# M2354 register map
File version: 1.0
Registers are 32-bit, read-write, reset 0x0 unless marked. A register's access mark holds for its fields unless they carry their own. Offsets are from the block's base; [hi:lo] are bit positions; lines under a group give offsets from that group; {n}, {i} and the like mark numbered series; 'fields as' and 'values as' point back to an identical list.

## CLK_NS — CLK Register Map
Base 0x50000200
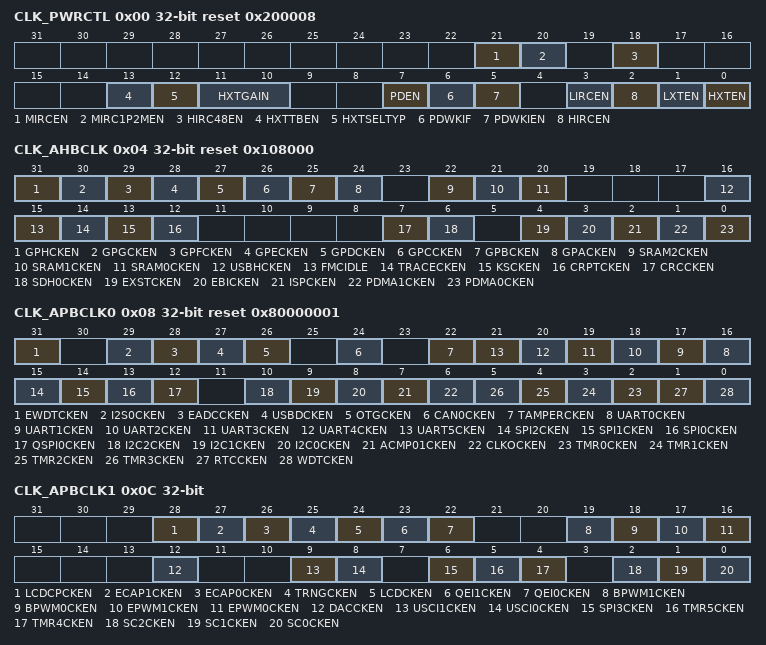
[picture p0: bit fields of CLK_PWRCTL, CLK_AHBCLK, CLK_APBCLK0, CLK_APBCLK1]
0x00 CLK_PWRCTL reset 0x200008 (reset mask 0xFFF000FF) — System Power-down Control Register
  [21] MIRCEN — MIRC Enable Bit (Write Protect). Note 1: This bit is write protected. Refer to the SYS_REGLCTL register. Note 2: MIRC cannot be disabled and MIRCEN will read as 1 if HCLK clock source is selected from MIRC.
    0=4 MHz internal medium speed RC oscillator (MIRC) Disabled; 1=4 MHz internal medium speed RC oscillator (MIRC) Enabled
  [20] MIRC1P2MEN — MIRC1P2M Enable Bit (Write Protect). Note 1: This bit is write protected. Refer to the SYS_REGLCTL register. Note 2: This clock source only for LCD use.
    0=1.2 MHz internal medium speed RC oscillator (MIRC1P2M) Disabled; 1=1.2 MHz internal medium speed RC oscillator (MIRC1P2M) Enabled
  [18] HIRC48EN — HIRC48 Enable Bit (Write Protect). Note 1: This bit is write protected. Refer to the SYS_REGLCTL register. Note 2: HIRC48 cannot be disabled and HIRC48EN will read as 1 if HCLK clock source is selected from HIRC48.
    0=48 MHz internal high speed RC oscillator (HIRC48) Disabled; 1=48 MHz internal high speed RC oscillator (HIRC48) Enabled
  [13] HXTTBEN — HXT Crystal TURBO Mode (Write Protect). Note: This bit is write protected. Refer to the SYS_REGLCTL register.
    0=HXT Crystal TURBO mode Disabled; 1=HXT Crystal TURBO mode Enabled
  [12] HXTSELTYP — HXT Crystal Type Select Bit (Write Protect). Note: This bit is write protected. Refer to the SYS_REGLCTL register.
    0=Select INV type; 1=Select GM type
  [11:10] HXTGAIN — HXT Gain Control Bit (Write Protect). Gain control is used to enlarge the gain of crystal to make sure crystal work normally. If gain control is enabled, crystal will consume more power than gain control off. Note: These bits are write protected. Refer to the SYS_REGLCTL register.
    0=HXT frequency is lower than from 8 MHz; 1=HXT frequency is from 8 MHz to 12 MHz; 2=HXT frequency is from 12 MHz to 16 MHz; 3=HXT frequency is higher than 16 MHz
  [7] PDEN — System Power-down Enable (Write Protect). When this bit is set to 1, Power-down mode is enabled and the chip keeps active till the CPU sleep mode is also active and then the chip enters Power-down mode. When chip wakes up from Power-down mode, this bit is auto cleared. Users need to set this bit again for next Power-down. In Power-down mode, HXT, HIRC, HIRC48, PLL and system clock will be disabled and ignored the clock source selection. The clocks of peripheral are not controlled by Power-down mode, if the peripheral clock source is from LXT, LIRC or MIRC. Note: This bit is write protected. Refer to the SYS_REGLCTL register.
    0=Chip operating normally or chip in idle mode because of WFI command; 1=Chip waits CPU sleep command WFI and then enters Power-down mode
  [6] PDWKIF — Power-down Mode Wake-up Interrupt Status. Set by 'Power-down wake-up event', it indicates that resume from Power-down mode' The flag is set if the EINT7~0, GPIO, UART0~5, USBH, USBD, OTG, CAN0, BOD, ACMP, WDT, EWDT, SDH0, TIMER, I2C0~2, USCI0~1, RTC, TAMPER and CLKD wake-up occurred. Note 1: Write 1 to clear the bit to 0. Note 2: This bit works only if PDWKIEN (CLK_PWRCTL[5]) set to 1.
  [5] PDWKIEN — Power-down Mode Wake-up Interrupt Enable Bit (Write Protect). Note 1: The interrupt will occur when both PDWKIF and PDWKIEN are high, after resume from power-down mode. Note 2: This bit is write protected. Refer to the SYS_REGLCTL register.
    0=Power-down mode wake-up interrupt Disabled; 1=Power-down mode wake-up interrupt Enabled
  [3] LIRCEN — LIRC Enable Bit (Write Protect). Note 1: This bit is write protected. Refer to the SYS_REGLCTL register. Note 2: LIRC cannot be disabled and LIRCEN will read as 1 if HCLK clock source is selected from LIRC. Note 3: If CWDTEN(CONFIG0[31,4:3]) is set to 111, LIRC clock can be enabled or disabled by setting LIRCEN(CLK_PWRCTL[3]). If CWDTEN(CONFIG0[31,4:3]) is not set to 111, LIRC cannot be disabled in normal mode. In Power-down mode, LIRC clock is controlled by LIRCEN(CLK_PWRCTL[3]) and CWDTPDEN(CONFIG0[30]) setting.
    0=32 kHz internal low speed RC oscillator (LIRC) Disabled; 1=32 kHz internal low speed RC oscillator (LIRC) Enabled
  [2] HIRCEN — HIRC Enable Bit (Write Protect). Note 1: This bit is write protected. Refer to the SYS_REGLCTL register. Note 2: HIRC cannot be disabled and HIRCEN will read as 1 if HCLK clock source is selected from HIRC or PLL (clock source from HIRC).
    0=12 MHz internal high speed RC oscillator (HIRC) Disabled; 1=12 MHz internal high speed RC oscillator (HIRC) Enabled
  [1] LXTEN — LXT Enable Bit (Write Protect). Note 1: This bit is write protected. Refer to the SYS_REGLCTL register. Note 2: LXT cannot be disabled and LXTEN will read as 1 if HCLK clock source is selected from LXT when the LXT clock source is selected as extLXT by setting C32KSEL(RTC_LXTCTL[6]) to 1.
    0=32.768 kHz external low speed crystal (extLXT) Disabled; 1=32.768 kHz external low speed crystal (extLXT) Enabled
  [0] HXTEN — HXT Enable Bit (Write Protect). Note 1: This bit is write protected. Refer to the SYS_REGLCTL register. Note 2: HXT cannot be disabled and HXTEN will read as 1 if HCLK clock source is selected from HXT or PLL (clock source from HXT).
    0=4~24 MHz external high speed crystal (HXT) Disabled; 1=4~24 MHz external high speed crystal (HXT) Enabled
0x04 CLK_AHBCLK reset 0x108000 — AHB Devices Clock Enable Register
  [31] GPHCKEN — GPIOH Clock Enable Bit
    0=GPIOH port clock Disabled; 1=GPIOH port clock Enabled
  [30] GPGCKEN — GPIOG Clock Enable Bit
    0=GPIOG port clock Disabled; 1=GPIOG port clock Enabled
  [29] GPFCKEN — GPIOF Clock Enable Bit
    0=GPIOF port clock Disabled; 1=GPIOF port clock Enabled
  [28] GPECKEN — GPIOE Clock Enable Bit
    0=GPIOE port clock Disabled; 1=GPIOE port clock Enabled
  [27] GPDCKEN — GPIOD Clock Enable Bit
    0=GPIOD port clock Disabled; 1=GPIOD port clock Enabled
  [26] GPCCKEN — GPIOC Clock Enable Bit
    0=GPIOC port clock Disabled; 1=GPIOC port clock Enabled
  [25] GPBCKEN — GPIOB Clock Enable Bit
    0=GPIOB port clock Disabled; 1=GPIOB port clock Enabled
  [24] GPACKEN — GPIOA Clock Enable Bit
    0=GPIOA port clock Disabled; 1=GPIOA port clock Enabled
  [22] SRAM2CKEN — SRAM Bank2 Controller Clock Enable Bit
    0=SRAM bank2 clock Disabled; 1=SRAM bank2 clock Enabled
  [21] SRAM1CKEN — SRAM Bank1 Controller Clock Enable Bit
    0=SRAM bank1 clock Disabled; 1=SRAM bank1 clock Enabled
  [20] SRAM0CKEN — SRAM Bank0 Controller Clock Enable Bit
    0=SRAM bank0 clock Disabled; 1=SRAM bank0 clock Enabled
  [16] USBHCKEN — USB HOST 1.1 Controller Clock Enable Bit
    0=USB HOST 1.1 peripheral clock Disabled; 1=USB HOST 1.1 peripheral clock Enabled
  [15] FMCIDLE — Flash Memory Controller Clock Enable Bit in IDLE Mode
    0=FMC clock Disabled when chip is under IDLE mode; 1=FMC clock Enabled when chip is under IDLE mode
  [14] TRACECKEN — Trace Clock Enable Bit
    0=Trace clock Disabled; 1=Trace clock Enabled
  [13] KSCKEN — Key Store Clock Enable Bit
    0=Key store clock Disabled; 1=Key store clock Enabled
  [12] CRPTCKEN — Cryptographic Accelerator Clock Enable Bit
    0=Cryptographic Accelerator clock Disabled; 1=Cryptographic Accelerator clock Enabled
  [7] CRCCKEN — CRC Generator Controller Clock Enable Bit
    0=CRC peripheral clock Disabled; 1=CRC peripheral clock Enabled
  [6] SDH0CKEN — SDHOST0 Controller Clock Enable Bit
    0=SDHOST0 peripheral clock Disabled; 1=SDHOST0 peripheral clock Enabled
  [4] EXSTCKEN — External System Tick Clock Enable Bit
    0=External System tick clock Disabled; 1=External System tick clock Enabled
  [3] EBICKEN — EBI Controller Clock Enable Bit
    0=EBI peripheral clock Disabled; 1=EBI peripheral clock Enabled
  [2] ISPCKEN — Flash ISP Controller Clock Enable Bit
    0=Flash ISP peripheral clock Disabled; 1=Flash ISP peripheral clock Enabled
  [1] PDMA1CKEN — PDMA1 Controller Clock Enable Bit
    0=PDMA1 peripheral clock Disabled; 1=PDMA1 peripheral clock Enabled
  [0] PDMA0CKEN — PDMA0 Controller Clock Enable Bit (Secure)
    0=PDMA0 peripheral clock Disabled; 1=PDMA0 peripheral clock Enabled
0x08 CLK_APBCLK0 reset 0x80000001 — APB Devices Clock Enable Register 0
  [31] EWDTCKEN — Extra Watchdog Timer Clock Enable Bit (Write Protect). Note: This bit is write protected. Refer to the SYS_REGLCTL register.
    0=Extra Watchdog timer and Windows watchdog timer clock Disabled; 1=Extra Watchdog timer and Windows watchdog timer clock Enabled
  [29] I2S0CKEN — I2S0 Clock Enable Bit
    0=I2S0 Clock Disabled; 1=I2S0 Clock Enabled
  [28] EADCCKEN — Enhanced Analog-digital-converter (EADC) Clock Enable Bit
    0=EADC clock Disabled; 1=EADC clock Enabled
  [27] USBDCKEN — USB Device Clock Enable Bit
    0=USB Device clock Disabled; 1=USB Device clock Enabled
  [26] OTGCKEN — USB OTG Clock Enable Bit
    0=USB OTG clock Disabled; 1=USB OTG clock Enabled
  [24] CAN0CKEN — CAN0 Clock Enable Bit
    0=CAN0 clock Disabled; 1=CAN0 clock Enabled
  [22] TAMPERCKEN — TAMPER Clock Enable Bit
    0=Tamper clock Disabled; 1=Tamper clock Enabled
  [n+16] UART{n}CKEN (n=0..5) — UART{n} Clock Enable Bit
    0=UART{n} clock Disabled; 1=UART{n} clock Enabled
  [15] SPI2CKEN — SPI2 Clock Enable Bit
    0=SPI2 clock Disabled; 1=SPI2 clock Enabled
  [14] SPI1CKEN — SPI1 Clock Enable Bit
    0=SPI1 clock Disabled; 1=SPI1 clock Enabled
  [13] SPI0CKEN — SPI0 Clock Enable Bit
    0=SPI0 clock Disabled; 1=SPI0 clock Enabled
  [12] QSPI0CKEN — QSPI0 Clock Enable Bit
    0=QSPI0 clock Disabled; 1=QSPI0 clock Enabled
  [10] I2C2CKEN — I2C2 Clock Enable Bit
    0=I2C2 clock Disabled; 1=I2C2 clock Enabled
  [9] I2C1CKEN — I2C1 Clock Enable Bit
    0=I2C1 clock Disabled; 1=I2C1 clock Enabled
  [8] I2C0CKEN — I2C0 Clock Enable Bit
    0=I2C0 clock Disabled; 1=I2C0 clock Enabled
  [7] ACMP01CKEN — Analog Comparator 0/1 Clock Enable Bit
    0=Analog comparator 0/1 clock Disabled; 1=Analog comparator 0/1 clock Enabled
  [6] CLKOCKEN — CLKO Clock Enable Bit
    0=CLKO clock Disabled; 1=CLKO clock Enabled
  [n+2] TMR{n}CKEN (n=0..3) — Timer{n} Clock Enable Bit
    0=Timer{n} clock Disabled; 1=Timer{n} clock Enabled
  [1] RTCCKEN — Real-time-clock APB Interface Clock Enable Bit. This bit is used to control the RTC APB clock only. The RTC peripheral clock source is selected from RTCCKSEL(RTC_LXTCTL[7]). It can be selected to 32.768 kHz external low speed crystal (LXT) or 32 kHz internal low speed RC oscillator (LIRC).
    0=RTC clock Disabled; 1=RTC clock Enabled
  [0] WDTCKEN — Watchdog Timer Clock Enable Bit (Write Protect). Note: This bit is write protected. Refer to the SYS_REGLCTL register.
    0=Watchdog timer and Windows watchdog timer clock Disabled; 1=Watchdog timer and Windows watchdog timer clock Enabled
0x0C CLK_APBCLK1 — APB Devices Clock Enable Register 1
  [28] LCDCPCKEN — LCD Charge Pump Clock Enable Bit
    0=LCD charge pump clock Disabled; 1=LCD charge pump clock Enabled
  [27] ECAP1CKEN — ECAP1 Clock Enable Bit
    0=ECAP1 clock Disabled; 1=ECAP1 clock Enabled
  [26] ECAP0CKEN — ECAP0 Clock Enable Bit
    0=ECAP0 clock Disabled; 1=ECAP0 clock Enabled
  [25] TRNGCKEN — TRNG Clock Enable Bit
    0=TRNG clock Disabled; 1=TRNG clock Enabled
  [24] LCDCKEN — LCD Clock Enable Bit
    0=LCD clock Disabled; 1=LCD clock Enabled
  [23] QEI1CKEN — QEI1 Clock Enable Bit
    0=QEI1 clock Disabled; 1=QEI1 clock Enabled
  [22] QEI0CKEN — QEI0 Clock Enable Bit
    0=QEI0 clock Disabled; 1=QEI0 clock Enabled
  [19] BPWM1CKEN — BPWM1 Clock Enable Bit
    0=BPWM1 clock Disabled; 1=BPWM1 clock Enabled
  [18] BPWM0CKEN — BPWM0 Clock Enable Bit
    0=BPWM0 clock Disabled; 1=BPWM0 clock Enabled
  [17] EPWM1CKEN — EPWM1 Clock Enable Bit
    0=EPWM1 clock Disabled; 1=EPWM1 clock Enabled
  [16] EPWM0CKEN — EPWM0 Clock Enable Bit
    0=EPWM0 clock Disabled; 1=EPWM0 clock Enabled
  [12] DACCKEN — DAC Clock Enable Bit
    0=DAC clock Disabled; 1=DAC clock Enabled
  [9] USCI1CKEN — USCI1 Clock Enable Bit
    0=USCI1 clock Disabled; 1=USCI1 clock Enabled
  [8] USCI0CKEN — USCI0 Clock Enable Bit
    0=USCI0 clock Disabled; 1=USCI0 clock Enabled
  [6] SPI3CKEN — SPI3 Clock Enable Bit
    0=SPI3 clock Disabled; 1=SPI3 clock Enabled
  [5] TMR5CKEN — Timer5 Clock Enable Bit
    0=Timer5 clock Disabled; 1=Timer5 clock Enabled
  [4] TMR4CKEN — Timer4 Clock Enable Bit
    0=Timer4 clock Disabled; 1=Timer4 clock Enabled
  [2] SC2CKEN — Smart Card 2 (SC2) Clock Enable Bit
    0=SC2 clock Disabled; 1=SC2 clock Enabled
  [1] SC1CKEN — Smart Card 1 (SC1) Clock Enable Bit
    0=SC1 clock Disabled; 1=SC1 clock Enabled
  [0] SC0CKEN — Smart Card 0 (SC0) Clock Enable Bit
    0=SC0 clock Disabled; 1=SC0 clock Enabled
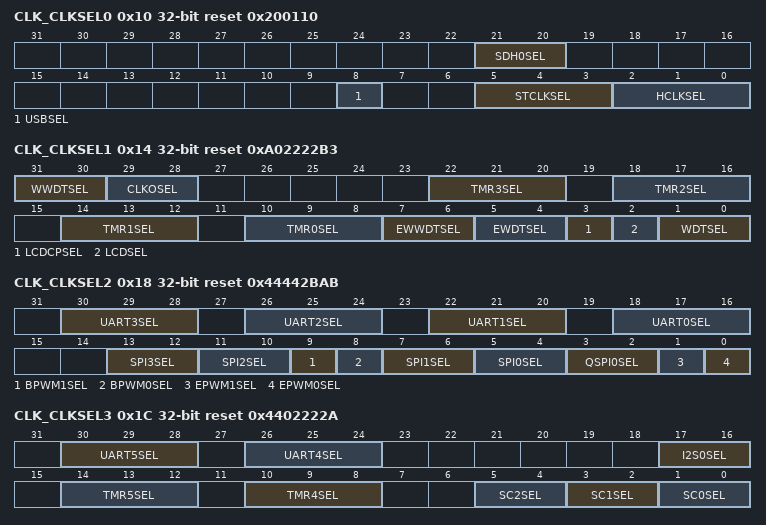
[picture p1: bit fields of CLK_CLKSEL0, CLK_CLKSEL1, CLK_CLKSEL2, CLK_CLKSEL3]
0x10 CLK_CLKSEL0 reset 0x200110 (reset mask 0xFFFFFFF0) — Clock Source Select Register 0
  [21:20] SDH0SEL — SDHOST0 Peripheral Clock Source Selection (Write Protect). Note: These bits are write protected. Refer to the SYS_REGLCTL register.
    0=Clock source from HXT clock; 1=Clock source from PLL clock; 2=Clock source from HCLK; 3=Clock source from HIRC clock
  [8] USBSEL — USB Clock Source Selection (Write Protect)
    0=Clock source from HIRC48; 1=Clock source from PLL
  [5:3] STCLKSEL — SysTick Clock Source Selection (Write Protect). Note 2: These bits are write protected. Refer to the SYS_REGLCTL register.
    0=Clock source from HXT; 1=Clock source from LXT; 2=Clock source from HXT/2; 3=Clock source from HCLK/2; 7=Clock source from HIRC/2
  [2:0] HCLKSEL — HCLK Clock Source Selection (Write Protect). Before clock switching, the related clock sources (both pre-select and new-select) must be turned on. Note: These bits are write protected. Refer to the SYS_REGLCTL register.
    0=Clock source from HXT; 1=Clock source from LXT; 2=Clock source from PLL; 3=Clock source from LIRC; 5=Clock source from HIRC48; 6=Clock source from MIRC; 7=Clock source from HIRC
0x14 CLK_CLKSEL1 reset 0xA02222B3 — Clock Source Select Register 1
  [31:30] WWDTSEL — Window Watchdog Timer Clock Source Selection (Write Protect). Note: These bits are write protected. Refer to the SYS_REGLCTL register.
    2=Clock source from HCLK/2048; 3=Clock source from 32 kHz internal low speed RC oscillator (LIRC)
  [29:28] CLKOSEL — Clock Output Clock Source Selection
    0=Clock source from 4~24 MHz external high speed crystal oscillator (HXT); 1=Clock source from 32.768 kHz external low speed crystal oscillator (LXT); 2=Clock source from HCLK; 3=Clock source from 12 MHz internal high speed RC oscillator (HIRC)
  [22:20] TMR3SEL — TIMER3 Clock Source Selection
    0=Clock source from 4~24 MHz external high speed crystal oscillator (HXT); 1=Clock source from 32.768 kHz external low speed crystal oscillator (LXT); 2=Clock source from PCLK1; 3=Clock source from external clock TM3 pin; 5=Clock source from 32 kHz internal low speed RC oscillator (LIRC); 7=Clock source from 12 MHz internal high speed RC oscillator (HIRC)
  [18:16] TMR2SEL — TIMER2 Clock Source Selection
    0=Clock source from 4~24 MHz external high speed crystal oscillator (HXT); 1=Clock source from 32.768 kHz external low speed crystal oscillator (LXT); 2=Clock source from PCLK1; 3=Clock source from external clock TM2 pin; 5=Clock source from 32 kHz internal low speed RC oscillator (LIRC); 7=Clock source from 12 MHz internal high speed RC oscillator (HIRC)
  [14:12] TMR1SEL — TIMER1 Clock Source Selection
    0=Clock source from 4~24 MHz external high speed crystal oscillator (HXT); 1=Clock source from 32.768 kHz external low speed crystal oscillator (LXT); 2=Clock source from PCLK0; 3=Clock source from external clock TM1 pin; 5=Clock source from 32 kHz internal low speed RC oscillator (LIRC); 7=Clock source from 12 MHz internal high speed RC oscillator (HIRC)
  [10:8] TMR0SEL — TIMER0 Clock Source Selection
    0=Clock source from 4~24 MHz external high speed crystal oscillator (HXT); 1=Clock source from 32.768 kHz external low speed crystal oscillator (LXT); 2=Clock source from PCLK0; 3=Clock source from external clock TM0 pin; 5=Clock source from 32 kHz internal low speed RC oscillator (LIRC); 7=Clock source from 12 MHz internal high speed RC oscillator (HIRC)
  [7:6] EWWDTSEL — Extra Window Watchdog Timer Clock Source Selection (Write Protect). Note: These bits are write protected. Refer to the SYS_REGLCTL register.
    values as WWDTSEL
  [5:4] EWDTSEL — Extra Watchdog Timer Clock Source Selection (Write Protect). Note: These bits are write protected. Refer to the SYS_REGLCTL register.
    1=Clock source from 32.768 kHz external low speed crystal oscillator (LXT); 2=Clock source from HCLK/2048; 3=Clock source from 32 kHz internal low speed RC oscillator (LIRC)
  [3] LCDCPSEL — LCD Charge Pump Clock Source Selection
    0=Clock source from 1.2 MHz internal medium speed RC oscillator (MIRC1P2M); 1=Clock source from 4 MHz internal medium speed RC oscillator (MIRC)
  [2] LCDSEL — LCD Clock Source Selection
    0=Clock source from 32 kHz internal low speed RC oscillator (LIRC); 1=Clock source from 32.768 kHz external low speed crystal oscillator (LXT)
  [1:0] WDTSEL — Watchdog Timer Clock Source Selection (Write Protect). Note: These bits are write protected. Refer to the SYS_REGLCTL register.
    values as EWDTSEL
0x18 CLK_CLKSEL2 reset 0x44442BAB — Clock Source Select Register 2
  [30:28] UART3SEL — UART3 Clock Source Selection
    0=Clock source from 4~24 MHz external high speed crystal oscillator (HXT); 1=Clock source from PLL; 2=Clock source from 32.768 kHz external low speed crystal oscillator (LXT); 3=Clock source from 12 MHz internal high speed RC oscillator (HIRC); 4=Clock source from PCLK1
  [26:24] UART2SEL — UART2 Clock Source Selection
    0=Clock source from 4~24 MHz external high speed crystal oscillator (HXT); 1=Clock source from PLL; 2=Clock source from 32.768 kHz external low speed crystal oscillator (LXT); 3=Clock source from 12 MHz internal high speed RC oscillator (HIRC); 4=Clock source from PCLK0
  [22:20] UART1SEL — UART1 Clock Source Selection
    values as UART3SEL
  [18:16] UART0SEL — UART0 Clock Source Selection
    values as UART2SEL
  [13:12] SPI3SEL — SPI3 Clock Source Selection
    0=Clock source from 4~24 MHz external high speed crystal oscillator (HXT); 1=Clock source from PLL; 2=Clock source from PCLK0; 3=Clock source from 12 MHz internal high speed RC oscillator (HIRC)
  [11:10] SPI2SEL — SPI2 Clock Source Selection
    0=Clock source from 4~24 MHz external high speed crystal oscillator (HXT); 1=Clock source from PLL; 2=Clock source from PCLK1; 3=Clock source from 12 MHz internal high speed RC oscillator (HIRC)
  [9] BPWM1SEL ro — BPWM1 Clock Source Selection (Read Only). The peripheral clock source of BPWM1 is defined by BPWM1SEL.
    1=Clock source from PCLK1
  [8] BPWM0SEL ro — BPWM0 Clock Source Selection (Read Only). The peripheral clock source of BPWM0 is defined by BPWM0SEL.
    1=Clock source from PCLK0
  [7:6] SPI1SEL — SPI1 Clock Source Selection
    values as SPI3SEL
  [5:4] SPI0SEL — SPI0 Clock Source Selection
    values as SPI2SEL
  [3:2] QSPI0SEL — QSPI0 Clock Source Selection
    values as SPI3SEL
  [1] EPWM1SEL ro — EPWM1 Clock Source Selection (Read Only). The peripheral clock source of EPWM1 is defined by EPWM1SEL.
    1=Clock source from PCLK1
  [0] EPWM0SEL ro — EPWM0 Clock Source Selection (Read Only). The peripheral clock source of EPWM0 is defined by EPWM0SEL.
    1=Clock source from PCLK0
0x1C CLK_CLKSEL3 reset 0x4402222A — Clock Source Select Register 3
  [30:28] UART5SEL — UART5 Clock Source Selection
    values as CLK_CLKSEL2.UART3SEL
  [26:24] UART4SEL — UART4 Clock Source Selection
    values as CLK_CLKSEL2.UART2SEL
  [17:16] I2S0SEL — I2S0 Clock Source Selection
    0=Clock source from HXT clock; 1=Clock source from PLL clock; 2=Clock source from PCLK0; 3=Clock source from HIRC clock
  [14:12] TMR5SEL — TIMER5 Clock Source Selection
    0=Clock source from 4~24 MHz external high speed crystal oscillator (HXT); 1=Clock source from 32.768 kHz external low speed crystal oscillator (LXT); 2=Clock source from PCLK0; 3=Clock source from external clock TM5 pin; 4=Clock source from 4 MHz internal medium speed RC oscillator (MIRC); 5=Clock source from 32 kHz internal low speed RC oscillator (LIRC); 7=Clock source from 12 MHz internal high speed RC oscillator (HIRC)
  [10:8] TMR4SEL — TIMER4 Clock Source Selection
    0=Clock source from 4~24 MHz external high speed crystal oscillator (HXT); 1=Clock source from 32.768 kHz external low speed crystal oscillator (LXT); 2=Clock source from PCLK0; 3=Clock source from external clock TM4 pin; 4=Clock source from 4 MHz internal medium speed RC oscillator (MIRC); 5=Clock source from 32 kHz internal low speed RC oscillator (LIRC); 7=Clock source from 12 MHz internal high speed RC oscillator (HIRC)
  [5:4] SC2SEL — Smart Card 2 (SC2) Clock Source Selection
    values as CLK_CLKSEL2.SPI3SEL
  [3:2] SC1SEL — Smart Card 1 (SC1) Clock Source Selection
    values as CLK_CLKSEL2.SPI2SEL
  [1:0] SC0SEL — Smart Card 0 (SC0) Clock Source Selection
    values as CLK_CLKSEL2.SPI3SEL
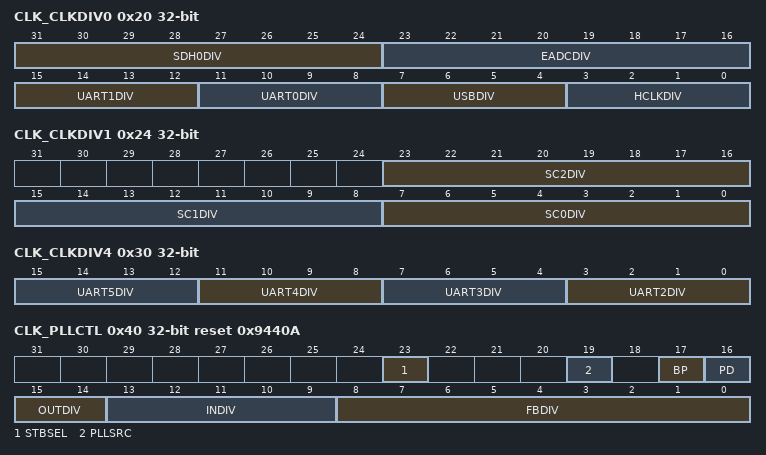
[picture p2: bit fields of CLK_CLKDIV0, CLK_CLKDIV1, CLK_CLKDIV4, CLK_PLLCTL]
0x20 CLK_CLKDIV0 (reset mask 0xFFFFFFF0) — Clock Divider Number Register 0
  [31:24] SDH0DIV — SDHOST0 Clock Divide Number From SDHOST0 Clock Source
  [23:16] EADCDIV — EADC Clock Divide Number From EADC Clock Source
  [15:12] UART1DIV — UART1 Clock Divide Number From UART1 Clock Source
  [11:8] UART0DIV — UART0 Clock Divide Number From UART0 Clock Source
  [7:4] USBDIV — USB Clock Divide Number From USB Clock Source
  [3:0] HCLKDIV — HCLK Clock Divide Number From HCLK Clock Source
0x24 CLK_CLKDIV1 — Clock Divider Number Register 1
  [23:16] SC2DIV — Smart Card 2 (SC2) Clock Divide Number From SC2 Clock Source
  [15:8] SC1DIV — Smart Card 1 (SC1) Clock Divide Number From SC1 Clock Source
  [7:0] SC0DIV — Smart Card 0 (SC0) Clock Divide Number From SC0 Clock Source
0x30 CLK_CLKDIV4 — Clock Divider Number Register 4
  [4n-5:4n-8] UART{n}DIV (n=2..5) — UART{n} Clock Divide Number From UART{n} Clock Source
0x40 CLK_PLLCTL reset 0x9440A — PLL Control Register
  [23] STBSEL — PLL Stable Counter Selection (Write Protect). Note: This bit is write protected. Refer to the SYS_REGLCTL register.
    0=PLL stable time is 1200 PLL source clock (suitable for source clock is equal to or less than 12 MHz); 1=PLL stable time is 2400 PLL source clock (suitable for source clock is larger than 12 MHz)
  [19] PLLSRC — PLL Source Clock Selection (Write Protect). Note: This bit is write protected. Refer to the SYS_REGLCTL register.
    0=PLL source clock from 4~24 MHz external high-speed crystal oscillator (HXT); 1=PLL source clock from 12 MHz internal high-speed oscillator (HIRC)
  [17] BP — PLL Bypass Control (Write Protect). Note: This bit is write protected. Refer to the SYS_REGLCTL register.
    0=PLL is in normal mode (default); 1=PLL clock output is same as PLL input clock FIN
  [16] PD — Power-down Mode (Write Protect). Note 1: If set the PDEN bit to 1 in CLK_PWRCTL register, the PLL will enter Power-down mode, too. Note 2: This bit is write protected. Refer to the SYS_REGLCTL register.
    0=PLL is enable (in normal mode); 1=PLL is disable (in Power-down mode) (default)
  [15:14] OUTDIV — PLL Output Divider Control (Write Protect). Refer to the formulas below the table. Note: These bits are write protected. Refer to the SYS_REGLCTL register.
  [13:9] INDIV — PLL Input Divider Control (Write Protect). Refer to the formulas below the table. Note: These bits are write protected. Refer to the SYS_REGLCTL register.
  [8:0] FBDIV — PLL Feedback Divider Control (Write Protect). Refer to the formulas below the table. Note: These bits are write protected. Refer to the SYS_REGLCTL register.
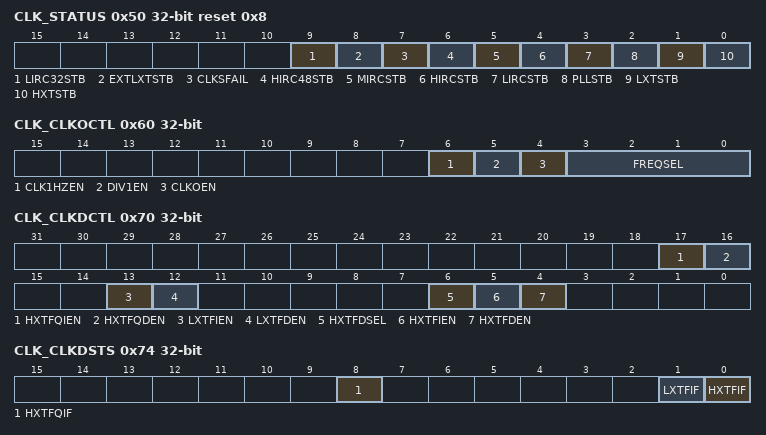
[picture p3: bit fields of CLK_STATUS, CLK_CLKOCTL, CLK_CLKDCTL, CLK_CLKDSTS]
0x50 CLK_STATUS ro reset 0x8 (reset mask 0xFFFFFF0F) — Clock Status Monitor Register
  [9] LIRC32STB — LIRC32 Clock Source Stable Flag (Read Only)
    0=32 kHz internal low speed RC oscillator (LIRC32) clock is not stable or disabled; 1=32 kHz internal low speed RC oscillator (LIRC32) clock is stable and enabled
  [8] EXTLXTSTB — EXTLXT Clock Source Stable Flag (Read Only)
    0=32.768 kHz external low speed crystal oscillator (extLXT) clock is not stable or disabled; 1=32.768 kHz external low speed crystal oscillator (extLXT) clock is stable and enabled
  [7] CLKSFAIL — Clock Switching Fail Flag (Read Only). This bit is updated when software switches system clock source. If switch target clock is stable, this bit will be set to 0. If switch target clock is not stable, this bit will be set to 1. Note: This bit is read only. After selected clock source is stable, hardware will switch system clock to selected clock automatically, and CLKSFAIL will be cleared automatically by hardware.
    0=Clock switching success; 1=Clock switching failure
  [6] HIRC48STB — HIRC48 Clock Source Stable Flag (Read Only)
    0=48 MHz internal high speed RC oscillator (HIRC48) clock is not stable or disabled; 1=48 MHz internal high speed RC oscillator (HIRC48) clock is stable and enabled
  [5] MIRCSTB — MIRC Clock Source Stable Flag (Read Only)
    0=4 MHz internal medium speed RC oscillator (MIRC) clock is not stable or disabled; 1=4 MHz internal medium speed RC oscillator (MIRC) clock is stable and enabled
  [4] HIRCSTB — HIRC Clock Source Stable Flag (Read Only)
    0=12 MHz internal high speed RC oscillator (HIRC) clock is not stable or disabled; 1=12 MHz internal high speed RC oscillator (HIRC) clock is stable and enabled
  [3] LIRCSTB — LIRC Clock Source Stable Flag (Read Only)
    0=32 kHz internal low speed RC oscillator (LIRC) clock is not stable or disabled; 1=32 kHz internal low speed RC oscillator (LIRC) clock is stable and enabled
  [2] PLLSTB — Internal PLL Clock Source Stable Flag (Read Only)
    0=Internal PLL clock is not stable or disabled; 1=Internal PLL clock is stable and enabled
  [1] LXTSTB — LXT Clock Source Stable Flag (Read Only). LXT clock source can be selected as extLXT or LIRC32 by setting C32KSEL(RTC_LXTCTL[6]). IfC32KSEL is set to 0 the LXT stable flag is set when extLXT clock source is stable. IfC32KSEL is set to 1 the LXT stable flag is set when LIRC32 clock source is stable.
    0=32.768 kHz external low speed crystal oscillator (LXT) clock is not stable or disabled; 1=32.768 kHz external low speed crystal oscillator (LXT) clock is stabled and enabled
  [0] HXTSTB — HXT Clock Source Stable Flag (Read Only)
    0=4~24 MHz external high speed crystal oscillator (HXT) clock is not stable or disabled; 1=4~24 MHz external high speed crystal oscillator (HXT) clock is stable and enabled
0x60 CLK_CLKOCTL — Clock Output Control Register
  [6] CLK1HZEN — Clock Output 1Hz Enable Bit
    0=1 Hz clock output for 32.768 kHz frequency compensation Disabled; 1=1 Hz clock output for 32.768 kHz frequency compensation Enabled
  [5] DIV1EN — Clock Output Divide One Enable Bit
    0=Clock Output will output clock with source frequency divided by FREQSEL; 1=Clock Output will output clock with source frequency
  [4] CLKOEN — Clock Output Enable Bit
    0=Clock Output function Disabled; 1=Clock Output function Enabled
  [3:0] FREQSEL — Clock Output Frequency Selection. The formula of output frequency is. Fin is the input clock frequency. Fout is the frequency of divider output clock. N is the 4-bit value of FREQSEL[3:0].
0x70 CLK_CLKDCTL — Clock Fail Detector Control Register
  [17] HXTFQIEN — HXT Clock Frequency Monitor Interrupt Enable Bit
    0=4~24 MHz external high speed crystal oscillator (HXT) clock frequency monitor fail interrupt Disabled; 1=4~24 MHz external high speed crystal oscillator (HXT) clock frequency monitor fail interrupt Enabled
  [16] HXTFQDEN — HXT Clock Frequency Monitor Enable Bit
    0=4~24 MHz external high speed crystal oscillator (HXT) clock frequency monitor Disabled; 1=4~24 MHz external high speed crystal oscillator (HXT) clock frequency monitor Enabled
  [13] LXTFIEN — LXT Clock Fail Interrupt Enable Bit
    0=32.768 kHz external low speed crystal oscillator (LXT) clock fail interrupt Disabled; 1=32.768 kHz external low speed crystal oscillator (LXT) clock fail interrupt Enabled
  [12] LXTFDEN — LXT Clock Fail Detector Enable Bit
    0=32.768 kHz external low speed crystal oscillator (LXT) clock fail detector Disabled; 1=32.768 kHz external low speed crystal oscillator (LXT) clock fail detector Enabled
  [6] HXTFDSEL — HXT Clock Fail Detector Selection. Note: When HXT Clock Fail Detector Selection is set, detector will keep detect whether HXT is stable or not, prevent HXT fail before stable.
    0=4~24 MHz external high speed crystal oscillator (HXT) clock fail detector after HXT stable; 1=4~24 MHz external high speed crystal oscillator (HXT) clock fail detector bypass HXT stable
  [5] HXTFIEN — HXT Clock Fail Interrupt Enable Bit
    0=4~24 MHz external high speed crystal oscillator (HXT) clock fail interrupt Disabled; 1=4~24 MHz external high speed crystal oscillator (HXT) clock fail interrupt Enabled
  [4] HXTFDEN — HXT Clock Fail Detector Enable Bit
    0=4~24 MHz external high speed crystal oscillator (HXT) clock fail detector Disabled; 1=4~24 MHz external high speed crystal oscillator (HXT) clock fail detector Enabled
0x74 CLK_CLKDSTS — Clock Fail Detector Status Register
  [8] HXTFQIF — HXT Clock Frequency Monitor Interrupt Flag (Write Protect). Note 1: Write 1 to clear the bit to 0. Note 2: This bit is write protected. Refer to the SYS_REGLCTL register.
    0=4~24 MHz external high speed crystal oscillator (HXT) clock is normal; 1=4~24 MHz external high speed crystal oscillator (HXT) clock frequency is abnormal
  [1] LXTFIF — LXT Clock Fail Interrupt Flag (Write Protect). Note 1: Write 1 to clear the bit to 0. Note 2: This bit is write protected. Refer to the SYS_REGLCTL register.
    0=32.768 kHz external low speed crystal oscillator (LXT) clock is normal; 1=32.768 kHz external low speed crystal oscillator (LXT) stops
  [0] HXTFIF — HXT Clock Fail Interrupt Flag (Write Protect). Note 1: Write 1 to clear the bit to 0. Note 2: This bit is write protected. Refer to the SYS_REGLCTL register.
    0=4~24 MHz external high speed crystal oscillator (HXT) clock is normal; 1=4~24 MHz external high speed crystal oscillator (HXT) clock stops
0x78 CLK_CDUPB — Clock Frequency Detector Upper Boundary Register
  [9:0] UPERBD — HXT Clock Frequency Detector Upper Boundary. The bits define the high value of frequency monitor window. When HXT frequency monitor value higher than this register, the HXT frequency detect fail interrupt flag will set to 1.
0x7C CLK_CDLOWB — Clock Frequency Detector Lower Boundary Register
  [9:0] LOWERBD — HXT Clock Frequency Detector Lower Boundary. The bits define the low value of frequency monitor window. When HXT frequency monitor value lower than this register, the HXT frequency detect fail interrupt flag will set to 1.
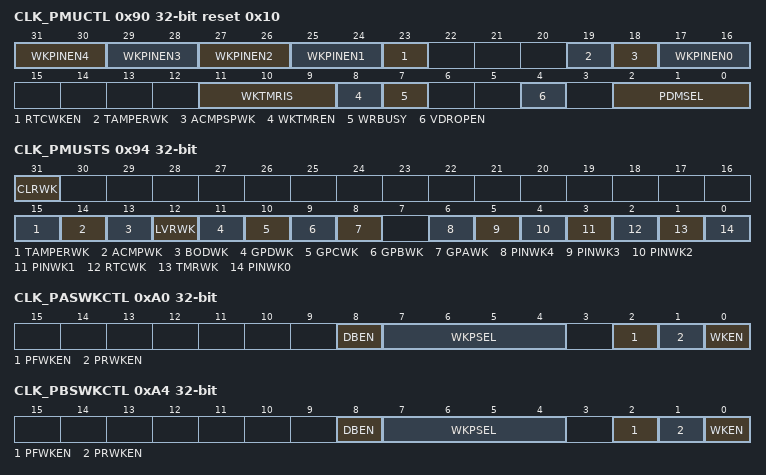
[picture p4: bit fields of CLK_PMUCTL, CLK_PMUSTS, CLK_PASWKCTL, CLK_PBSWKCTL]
0x90 CLK_PMUCTL reset 0x10 — Power Manager Control Register
  [31:30] WKPINEN4 — Wake-up Pin 4 Enable Bits (Write Protect). This is control register for GPF.6 to wake-up pin. Note: These bits are write protected. Refer to the SYS_REGLCTL register.
    0=Wake-up pin disable at Deep Power-down mode; 1=Wake-up pin rising edge enabled at Deep Power-down mode; 2=Wake-up pin falling edge enabled at Deep Power-down mode; 3=Wake-up pin both edge enabled at Deep Power-down mode
  [29:28] WKPINEN3 — Wake-up Pin 3 Enable Bits (Write Protect). This is control register for GPB.12 to wake-up pin. Note: These bits are write protected. Refer to the SYS_REGLCTL register.
    values as WKPINEN4
  [27:26] WKPINEN2 — Wake-up Pin 2 Enable Bits (Write Protect). This is control register for GPB.2 to wake-up pin. Note: These bits are write protected. Refer to the SYS_REGLCTL register.
    values as WKPINEN4
  [25:24] WKPINEN1 — Wake-up Pin 1 Enable Bits (Write Protect). This is control register for GPB.0 to wake-up pin. Note: These bits are write protected. Refer to the SYS_REGLCTL register.
    values as WKPINEN4
  [23] RTCWKEN — RTC Wake-up Enable Bit (Write Protect). Note: This bit is write protected. Refer to the SYS_REGLCTL register.
    0=RTC wake-up disable at Deep Power-down mode or Standby Power-down mode; 1=RTC wake-up enabled at Deep Power-down mode or Standby Power-down mode
  [19] TAMPERWK — Tamper Standby Power-down Mode Wake-up Enable Bit (Write Protect). Note: This bit is write protected. Refer to the SYS_REGLCTL register.
    0=Tamper wake-up disable at Standby Power-down mode; 1=Tamper wake-up enabled at Standby Power-down mode
  [18] ACMPSPWK — ACMP Standby Power-down Mode Wake-up Enable Bit (Write Protect). Note: This bit is write protected. Refer to the SYS_REGLCTL register.
    0=ACMP wake-up disable at Standby Power-down mode; 1=ACMP wake-up enabled at Standby Power-down mode
  [17:16] WKPINEN0 — Wake-up Pin 0 Enable Bits (Write Protect). This is control register for GPC.0 to wake-up pin. Note: These bits are write protected. Refer to the SYS_REGLCTL register.
    values as WKPINEN4
  [11:9] WKTMRIS — Wake-up Timer Time-out Interval Select Bits (Write Protect). These bits control wake-up timer time-out interval when chip under Deep Power-down mode or Standby Power-down mode. Note: These bits are write protected. Refer to the SYS_REGLCTL register.
    0=Time-out interval is 410 LIRC clocks (12.8ms); 1=Time-out interval is 819 LIRC clocks (25.6ms); 2=Time-out interval is 1638 LIRC clocks (51.2ms); 3=Time-out interval is 3277 LIRC clocks (102.4ms); 4=Time-out interval is 13107 LIRC clocks (409.6ms); 5=Time-out interval is 26214 LIRC clocks (819.2ms); 6=Time-out interval is 52429 LIRC clocks (1638.4ms); 7=Time-out interval is 209715 LIRC clocks (6553.6ms)
  [8] WKTMREN — Wake-up Timer Enable Bit (Write Protect). Note: This bit is write protected. Refer to the SYS_REGLCTL register.
    0=Wake-up timer disable at Deep Power-down mode or Standby Power-down mode; 1=Wake-up timer enabled at Deep Power-down mode or Standby Power-down mode
  [7] WRBUSY ro — Write Busy Flag (Read Only). If CLK_PMUCTL be written, this bit be asserted automatic by hardware, and be de-asserted when write procedure finish.
    0=CLK_PMUCTL write ready; 1=CLK_PMUCTL write ignore
  [4] VDROPEN — Standby Power-down mode Regulator Output Voltage Drop Enable Bit (Write Protect). If this bit be asserted, regulator output voltage drop to 0.9v when SPD mode. Note: This bit is write protected. Refer to the SYS_REGLCTL register.
    0=Regulator voltage auto drop function Disabled; 1=Regulator voltage auto drop function Enabled. (default)
  [2:0] PDMSEL — Power-down Mode Selection (Write Protect). These bits control chip power-down mode grade selection when CPU executes WFI/WFE instruction. Note: These bits are write protected. Refer to the SYS_REGLCTL register.
    0=Power-down mode is selected (PD); 1=Low leakage Power-down mode is selected (LLPD); 2=Fast wake-up Power-down (FWPD); 3=Ultra low leakage Power-down mode is selected (ULLPD); 4=Standby Power-down mode is selected (SPD); 6=Deep Power-down mode is selected (DPD)
0x94 CLK_PMUSTS — Power Manager Status Register
  [31] CLRWK — Clear Wake-up Flag. Note: This bit is auto cleared by hardware.
    0=No clear; 1=Clear all of wake-up flag
  [15] TAMPERWK ro — Tamper Wake-up Flag (Read Only). This flag indicates that wakeup of device from Standby Power-down mode (SPD) was requested with a Tamper event occurred. This flag is cleared when SPD mode is entered.
  [14] ACMPWK ro — ACMP Wake-up Flag (Read Only). This flag indicates that wakeup of device from Standby Power-down mode (SPD) was requested with a ACMP transition. This flag is cleared when SPD mode is entered.
  [13] BODWK ro — BOD Wake-up Flag (Read Only). This flag indicates that wakeup of device from Standby Power-down mode (SPD) was requested with a BOD happened. This flag is cleared when SPD mode is entered.
  [12] LVRWK ro — LVR Wake-up Flag (Read Only). This flag indicates that wakeup of device from Standby Power-down mode (SPD) was requested with a LVR happened. This flag is cleared when SPD mode is entered.
  [11] GPDWK ro — GPD Wake-up Flag (Read Only). This flag indicates that wake-up of chip from Standby Power-down mode (SPD) was requested by a transition of selected one GPD group pins. This flag is cleared when SPD mode is entered.
  [10] GPCWK ro — GPC Wake-up Flag (Read Only). This flag indicates that wake-up of chip from Standby Power-down mode (SPD) was requested by a transition of selected one GPC group pins. This flag is cleared when SPD mode is entered.
  [9] GPBWK ro — GPB Wake-up Flag (Read Only). This flag indicates that wake-up of chip from Standby Power-down mode (SPD) was requested by a transition of selected one GPB group pins. This flag is cleared when SPD mode is entered.
  [8] GPAWK ro — GPA Wake-up Flag (Read Only). This flag indicates that wake-up of chip from Standby Power-down mode (SPD) was requested by a transition of selected one GPA group pins. This flag is cleared when SPD mode is entered.
  [6] PINWK4 ro — Pin 4 Wake-up Flag (Read Only). This flag indicates that wake-up of chip from Deep Power-down mode (DPD) was requested by a transition of the Wake-up pin (GPF.6). This flag is cleared when DPD mode is entered.
  [5] PINWK3 ro — Pin 3 Wake-up Flag (Read Only). This flag indicates that wake-up of chip from Deep Power-down mode (DPD) was requested by a transition of the Wake-up pin (GPB.12). This flag is cleared when DPD mode is entered.
  [4] PINWK2 ro — Pin 2 Wake-up Flag (Read Only). This flag indicates that wake-up of chip from Deep Power-down mode (DPD) was requested by a transition of the Wake-up pin (GPB.2). This flag is cleared when DPD mode is entered.
  [3] PINWK1 ro — Pin 1 Wake-up Flag (Read Only). This flag indicates that wake-up of chip from Deep Power-down mode (DPD) was requested by a transition of the Wake-up pin (GPB.0). This flag is cleared when DPD mode is entered.
  [2] RTCWK ro — RTC Wake-up Flag (Read Only). This flag indicates that wakeup of device from Deep Power-down mode (DPD) or Standby Power-down (SPD) mode was requested with a RTC alarm, tick time or tamper happened. This flag is cleared when DPD or SPD mode is entered.
  [1] TMRWK ro — Timer Wake-up Flag (Read Only). This flag indicates that wake-up of chip from Deep Power-down mode (DPD) or Standby Power-down (SPD) mode was requested by wakeup timer time-out. This flag is cleared when DPD or SPD mode is entered.
  [0] PINWK0 ro — Pin 0 Wake-up Flag (Read Only). This flag indicates that wake-up of chip from Deep Power-down mode (DPD) was requested by a transition of the Wake-up pin (GPC.0). This flag is cleared when DPD mode is entered.
0x9C CLK_SWKDBCTL — Standby Power-down Wake-up De-bounce Control Register
  [3:0] SWKDBCLKSEL — Standby Power-down Wake-up De-bounce Sampling Cycle Selection. Note: De-bounce counter clock source is the 32 kHz internal low speed RC oscillator (LIRC).
    0=Sample wake-up input once per 1 clocks; 1=Sample wake-up input once per 2 clocks; 2=Sample wake-up input once per 4 clocks; 3=Sample wake-up input once per 8 clocks; 4=Sample wake-up input once per 16 clocks; 5=Sample wake-up input once per 32 clocks; 6=Sample wake-up input once per 64 clocks; 7=Sample wake-up input once per 128 clocks; 8=Sample wake-up input once per 256 clocks; 9=Sample wake-up input once per 2*256 clocks; 10=Sample wake-up input once per 4*256 clocks; 11=Sample wake-up input once per 8*256 clocks; 12=Sample wake-up input once per 16*256 clocks; 13=Sample wake-up input once per 32*256 clocks; 14=Sample wake-up input once per 64*256 clocks; 15=Sample wake-up input once per 128*256 clocks
0xA0 CLK_PASWKCTL — GPA Standby Power-down Wake-up Control Register
  [8] DBEN — GPA Input Signal De-bounce Enable Bit. The DBEN bit is used to enable the de-bounce function for each corresponding I/O. If the input signal pulse width cannot be sampled by continuous two de-bounce sample cycle, the input signal transition is seen as the signal bounce and will not trigger the wakeup.The de-bounce clock source is the 32 kHz internal low speed RC oscillator (LIRC). The de-bounce function is valid only for edge triggered.
    0=Standby power-down wake-up pin De-bounce function Disabled; 1=Standby power-down wake-up pin De-bounce function Enabled
  [7:4] WKPSEL — GPA Standby Power-down Wake-up Pin Select
    6=GPA.6 wake-up function Enabled; 7=GPA.7 wake-up function Enabled; 8=GPA.8 wake-up function Enabled; 9=GPA.9 wake-up function Enabled; 10=GPA.10 wake-up function Enabled; 11=GPA.11 wake-up function Enabled; 12=GPA.12 wake-up function Enabled; 13=GPA.13 wake-up function Enabled; 14=GPA.14 wake-up function Enabled; 15=GPA.15 wake-up function Enabled
  [2] PFWKEN — Pin Falling Edge Wake-up Enable Bit
    0=GPA group pin falling edge wake-up function Disabled; 1=GPA group pin falling edge wake-up function Enabled
  [1] PRWKEN — Pin Rising Edge Wake-up Enable Bit
    0=GPA group pin rising edge wake-up function Disabled; 1=GPA group pin rising edge wake-up function Enabled
  [0] WKEN — Standby Power-down Pin Wake-up Enable Bit
    0=GPA group pin wake-up function Disabled; 1=GPA group pin wake-up function Enabled
0xA4 CLK_PBSWKCTL — GPB Standby Power-down Wake-up Control Register
  [8] DBEN — GPB Input Signal De-bounce Enable Bit. The DBEN bit is used to enable the de-bounce function for each corresponding I/O. If the input signal pulse width cannot be sampled by continuous two de-bounce sample cycle, the input signal transition is seen as the signal bounce and will not trigger the wakeup.The de-bounce clock source is the 32 kHz internal low speed RC oscillator (LIRC). Note: The de-bounce function is valid only for edge triggered.
    values as CLK_PASWKCTL.DBEN
  [7:4] WKPSEL — GPB Standby Power-down Wake-up Pin Select
    0=GPB.0 wake-up function Enabled; 1=GPB.1 wake-up function Enabled; 2=GPB.2 wake-up function Enabled; 3=GPB.3 wake-up function Enabled; 4=GPB.4 wake-up function Enabled; 5=GPB.5 wake-up function Enabled; 6=GPB.6 wake-up function Enabled; 7=GPB.7 wake-up function Enabled; 8=GPB.8 wake-up function Enabled; 9=GPB.9 wake-up function Enabled; 10=GPB.10 wake-up function Enabled; 11=GPB.11 wake-up function Enabled; 12=GPB.12 wake-up function Enabled; 13=GPB.13 wake-up function Enabled; 14=GPB.14 wake-up function Enabled; 15=GPB.15 wake-up function Enabled
  [2] PFWKEN — Pin Falling Edge Wake-up Enable Bit
    0=GPB group pin falling edge wake-up function Disabled; 1=GPB group pin falling edge wake-up function Enabled
  [1] PRWKEN — Pin Rising Edge Wake-up Enable Bit
    0=GPB group pin rising edge wake-up function Disabled; 1=GPB group pin rising edge wake-up function Enabled
  [0] WKEN — Standby Power-down Pin Wake-up Enable Bit
    0=GPB group pin wake-up function Disabled; 1=GPB group pin wake-up function Enabled
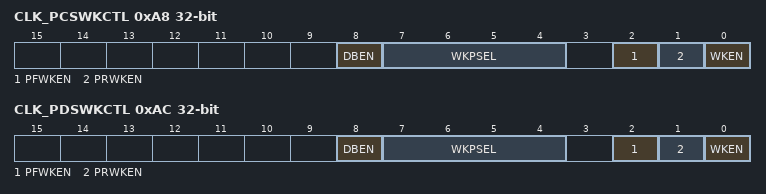
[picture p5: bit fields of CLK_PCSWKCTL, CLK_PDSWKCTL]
0xA8 CLK_PCSWKCTL — GPC Standby Power-down Wake-up Control Register
  [8] DBEN — GPC Input Signal De-bounce Enable Bit. The DBEN bit is used to enable the de-bounce function for each corresponding I/O. If the input signal pulse width cannot be sampled by continuous two de-bounce sample cycle, the input signal transition is seen as the signal bounce and will not trigger the wakeup.The de-bounce clock source is the 32 kHz internal low speed RC oscillator. The de-bounce function is valid only for edge triggered.
    values as CLK_PASWKCTL.DBEN
  [7:4] WKPSEL — GPC Standby Power-down Wake-up Pin Select
    0=GPC.0 wake-up function Enabled; 1=GPC.1 wake-up function Enabled; 2=GPC.2 wake-up function Enabled; 3=GPC.3 wake-up function Enabled; 4=GPC.4 wake-up function Enabled; 5=GPC.5 wake-up function Enabled; 6=GPC.6 wake-up function Enabled; 7=GPC.7 wake-up function Enabled; 8=GPC.8 wake-up function Enabled; 9=GPC.9 wake-up function Enabled; 10=GPC.10 wake-up function Enabled; 11=GPC.11 wake-up function Enabled; 12=GPC.12 wake-up function Enabled; 13=GPC.13 wake-up function Enabled
  [2] PFWKEN — Pin Falling Edge Wake-up Enable Bit
    0=GPC group pin falling edge wake-up function Disabled; 1=GPC group pin falling edge wake-up function Enabled
  [1] PRWKEN — Pin Rising Edge Wake-up Enable Bit
    0=GPC group pin rising edge wake-up function Disabled; 1=GPC group pin rising edge wake-up function Enabled
  [0] WKEN — Standby Power-down Pin Wake-up Enable Bit
    0=GPC group pin wake-up function Disabled; 1=GPC group pin wake-up function Enabled
0xAC CLK_PDSWKCTL — GPD Standby Power-down Wake-up Control Register
  [8] DBEN — GPD Input Signal De-bounce Enable Bit. The DBEN bit is used to enable the de-bounce function for each corresponding I/O. If the input signal pulse width cannot be sampled by continuous two de-bounce sample cycle, the input signal transition is seen as the signal bounce and will not trigger the wakeup.The de-bounce clock source is the 32 kHz internal low speed RC oscillator. Note: The de-bounce function is valid only for edge triggered.
    0=Standby power-down wake-up pin De-bounce function Disable; 1=Standby power-down wake-up pin De-bounce function Enable
  [7:4] WKPSEL — GPD Standby Power-down Wake-up Pin Select
    0=GPD.0 wake-up function Enabled; 1=GPD.1 wake-up function Enabled; 2=GPD.2 wake-up function Enabled; 3=GPD.3 wake-up function Enabled; 4=GPD.4 wake-up function Enabled; 5=GPD.5 wake-up function Enabled; 6=GPD.6 wake-up function Enabled; 7=GPD.7 wake-up function Enabled; 8=GPD.8 wake-up function Enabled; 9=GPD.9 wake-up function Enabled; 10=GPD.10 wake-up function Enabled; 11=GPD.11 wake-up function Enabled; 12=GPD.12 wake-up function Enabled; 14=GPD.14 wake-up function Enabled
  [2] PFWKEN — Pin Falling Edge Wake-up Enable Bit
    0=GPD group pin falling edge wake-up function Disabled; 1=GPD group pin falling edge wake-up function Enabled
  [1] PRWKEN — Pin Rising Edge Wake-up Enable Bit
    0=GPD group pin rising edge wake-up function Disabled; 1=GPD group pin rising edge wake-up function Enabled
  [0] WKEN — Standby Power-down Pin Wake-up Enable Bit
    0=GPD group pin wake-up function Disabled; 1=GPD group pin wake-up function Enabled
0xB0 CLK_IOPDCTL — GPIO Standby Power-down Control Register
  [0] IOHR — GPIO Hold Release. When GPIO enter standby power-down mode, all I/O status are hold to keep normal operating status. After chip was waked up from standby power-down mode, the I/O are still keep hold status until user set this bit to release I/O hold status. Note: This bit is auto cleared by hardware.
0xB4 CLK_HXTFSEL — HXT Filter Select Register
  [0] HXTFSEL — HXT Filter Select
    0=HXT cutoff frequency is 24 MHz; 1=HXT cutoff frequency is 4 MHz
